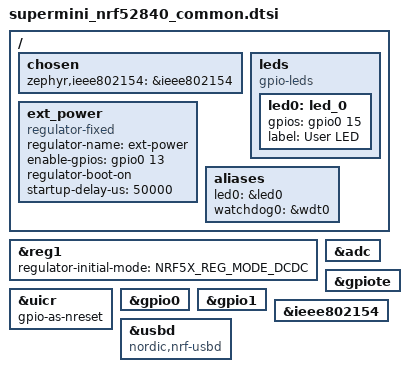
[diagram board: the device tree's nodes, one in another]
/*
 * Common devicetree for SuperMini nRF52840.
 * Pin-compatible with Nice!Nano v2.
 *
 * Header pinout (Pro Micro compatible, as in ZMK's nice_nano map):
 *   D0  = P0.08 (RX)      D1  = P0.06 (TX)
 *   D2  = P0.17           D3  = P0.20
 *   D4  = P0.22           D5  = P0.24
 *   D6  = P1.00           D7  = P0.11
 *   D8  = P1.04           D9  = P1.06
 *   D10 = P0.09 (NFC1)    D16 = P0.10 (NFC2)
 *   D14 = P1.11           D15 = P1.13
 *   D18 = P1.15           D19 = P0.02 (AIN0)
 *   D20 = P0.29 (AIN5)    D21 = P0.31 (AIN7)
 *
 * D10 and D16 stay NFC pins: &uicr does not set nfct-pins-as-gpios.
 *
 * Back side pads:
 *   P0.04 (AIN2)          P0.26
 *
 * P0.13 = VCC LDO enable (GPIO_ACTIVE_HIGH on v2/SuperMini)
 */

/dts-v1/;
#include <nordic/nrf52840_qiaa.dtsi>
#include "supermini_nrf52840-pinctrl.dtsi"

/ {
	chosen {
		zephyr,ieee802154 = &ieee802154;
	};

	leds {
		compatible = "gpio-leds";
		/* Red LED (active high) -- labeled as "blue" on Nice!Nano, colors are swapped on SuperMini */
		led0: led_0 {
			gpios = <&gpio0 15 GPIO_ACTIVE_HIGH>;
			label = "User LED";
		};
	};

	/*
	 * VCC rail control via the LDO enable pin. No driver binds this node
	 * until CONFIG_REGULATOR is set, so P0.13 stays at its reset state.
	 */
	ext_power {
		compatible = "regulator-fixed";
		regulator-name = "ext-power";
		enable-gpios = <&gpio0 13 GPIO_ACTIVE_HIGH>;
		regulator-boot-on;
		startup-delay-us = <50000>;
	};

	aliases {
		led0 = &led0;
		watchdog0 = &wdt0;
	};
};

/* Use DC/DC regulator for better power efficiency */
&reg1 {
	regulator-initial-mode = <NRF5X_REG_MODE_DCDC>;
};

&adc { status = "okay"; };
&uicr { gpio-as-nreset; };
&gpiote { status = "okay"; };
&gpio0 { status = "okay"; };
&gpio1 { status = "okay"; };

&ieee802154 { status = "okay"; };

zephyr_udc0: &usbd {
	compatible = "nordic,nrf-usbd";
	status = "okay";
};
